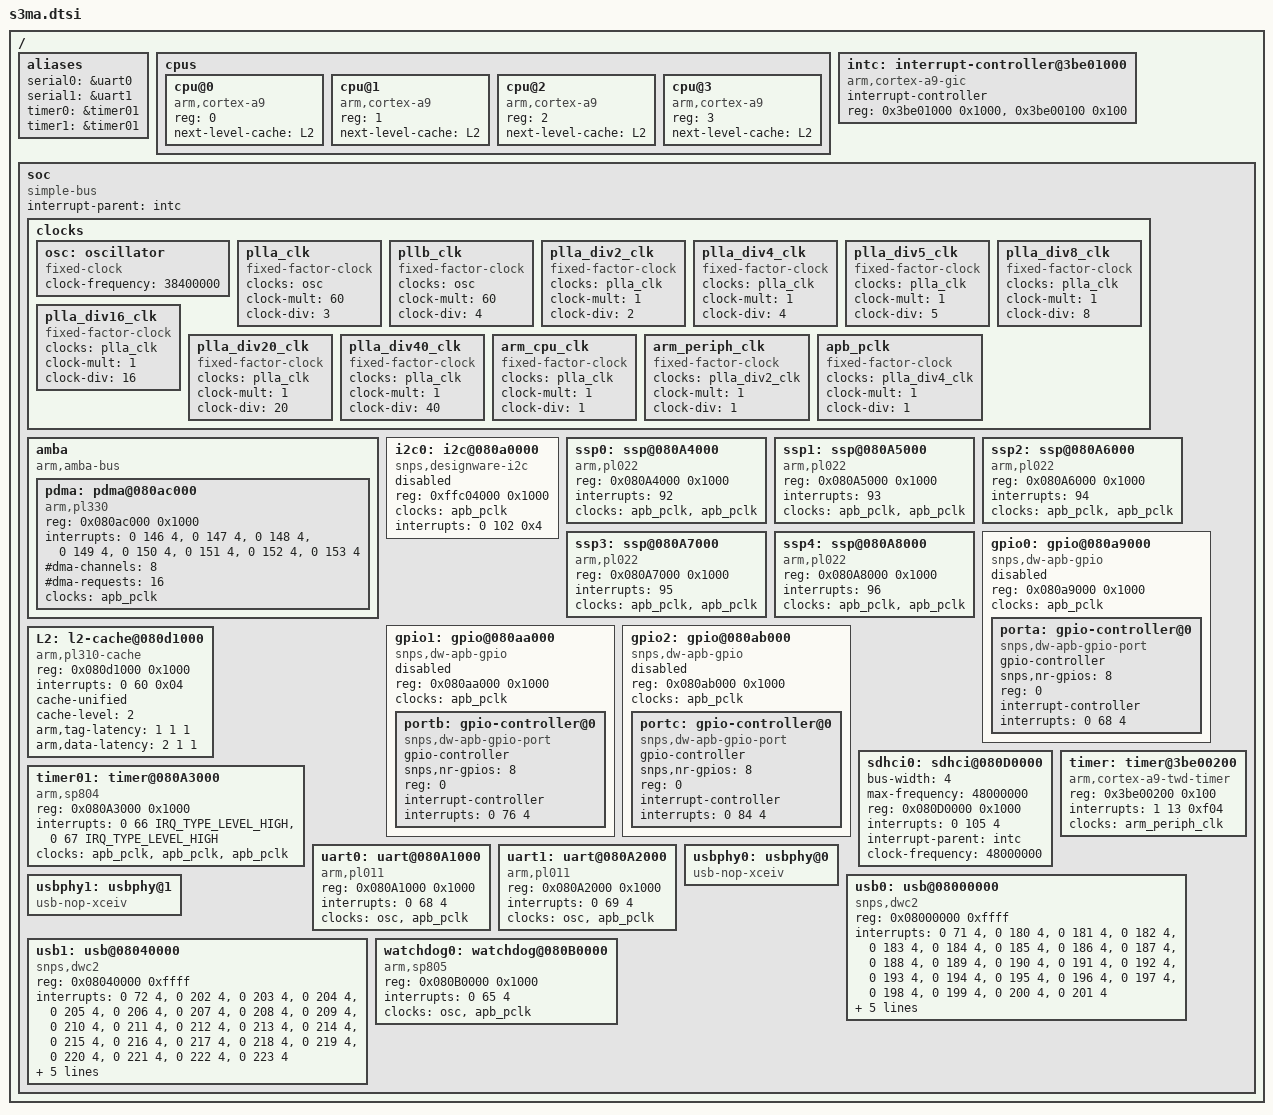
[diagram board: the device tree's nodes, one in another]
/*
 * Copyright 2015 Silver Bullet Technology
 *
 * This program is free software; you can redistribute it and/or modify
 * it under the terms of the GNU General Public License as published by
 * the Free Software Foundation; either version 2 of the License, or
 * (at your option) any later version.
 *
 * This program is distributed in the hope that it will be useful,
 * but WITHOUT ANY WARRANTY; without even the implied warranty of
 * MERCHANTABILITY or FITNESS FOR A PARTICULAR PURPOSE.  See the
 * GNU General Public License for more details.
 *
 * You should have received a copy of the GNU General Public License
 * along with this program.  If not, see <http://www.gnu.org/licenses/>.
 */

#include "skeleton.dtsi"
#include <dt-bindings/interrupt-controller/irq.h>
#include <dt-bindings/gpio/gpio.h>

/ {
	#address-cells = <1>;
	#size-cells = <1>;

	aliases {
		serial0 = &uart0;
		serial1 = &uart1;
		timer0 = &timer01;
		timer1 = &timer01;
	};

	cpus {
		#address-cells = <1>;
		#size-cells = <0>;

		cpu@0 {
			compatible = "arm,cortex-a9";
			device_type = "cpu";
			reg = <0>;
			next-level-cache = <&L2>;
		};
		cpu@1 {
			compatible = "arm,cortex-a9";
			device_type = "cpu";
			reg = <1>;
			next-level-cache = <&L2>;
		};
		cpu@2 {
			compatible = "arm,cortex-a9";
			device_type = "cpu";
			reg = <2>;
			next-level-cache = <&L2>;
		};
		cpu@3 {
			compatible = "arm,cortex-a9";
			device_type = "cpu";
			reg = <3>;
			next-level-cache = <&L2>;
		};
	};
	
	/* Add PMU */

	intc: interrupt-controller@3be01000 {
		compatible = "arm,cortex-a9-gic";
		#interrupt-cells = <3>;
		interrupt-controller;
		reg = <0x3be01000 0x1000>,
		      <0x3be00100 0x100>;
	};

	soc {
		#address-cells = <1>;
		#size-cells = <1>;
		compatible = "simple-bus";
		device_type = "soc";
		interrupt-parent = <&intc>;
		ranges;
		
		clocks {
			#address-cells = <1>;
			#size-cells = <0>;
	
			osc: oscillator {
				compatible = "fixed-clock";
				#clock-cells = <0>;
				clock-frequency = <38400000>;
                /* clock-output-names = "osc"; */
			};
			plla_clk: plla_clk {
				compatible = "fixed-factor-clock";
				#clock-cells = <0>;
				clocks = <&osc>;
				clock-mult = <60>;
				clock-div = <3>;
                /* clock-output-names = "plla_clk"; */
			};
			pllb_clk: pllb_clk {
				compatible = "fixed-factor-clock";
				#clock-cells = <0>;
				clocks = <&osc>;
				clock-mult = <60>;
				clock-div = <4>;
                /* clock-output-names = "pllb_clk"; */
			};
			plla_div2_clk: plla_div2_clk {
				compatible = "fixed-factor-clock";
				#clock-cells = <0>;
				clocks = <&plla_clk>;
				clock-mult = <1>;
				clock-div = <2>;
                /* clock-output-names = "plla_div2_clk"; */
			};
			plla_div4_clk: plla_div4_clk {
				compatible = "fixed-factor-clock";
				#clock-cells = <0>;
				clocks = <&plla_clk>;
				clock-mult = <1>;
				clock-div = <4>;
                /* clock-output-names = "plla_div4_clk"; */
			};
			plla_div5_clk: plla_div5_clk {
				compatible = "fixed-factor-clock";
				#clock-cells = <0>;
				clocks = <&plla_clk>;
				clock-mult = <1>;
				clock-div = <5>;
                /* clock-output-names = "plla_div5_clk"; */
			};
			plla_div8_clk: plla_div8_clk {
				compatible = "fixed-factor-clock";
				#clock-cells = <0>;
				clocks = <&plla_clk>;
				clock-mult = <1>;
				clock-div = <8>;
                /* clock-output-names = "plla_div8_clk"; */
			};
			plla_div16_clk: plla_div16_clk {
				compatible = "fixed-factor-clock";
				#clock-cells = <0>;
				clocks = <&plla_clk>;
				clock-mult = <1>;
				clock-div = <16>;
                /* clock-output-names = "plla_div16_clk"; */
			};			
			plla_div20_clk: plla_div20_clk {
				compatible = "fixed-factor-clock";
				#clock-cells = <0>;
				clocks = <&plla_clk>;
				clock-mult = <1>;
				clock-div = <20>;
                /* clock-output-names = "plla_div20_clk"; */
			};
			plla_div40_clk: plla_div40_clk {
				compatible = "fixed-factor-clock";
				#clock-cells = <0>;
				clocks = <&plla_clk>;
				clock-mult = <1>;
				clock-div = <40>;
                /* clock-output-names = "plla_div40_clk"; */
			};
			/* Generate the module clocks */
			arm_cpu_clk: arm_cpu_clk {
				compatible = "fixed-factor-clock";
				#clock-cells = <0>;
				clocks = <&plla_clk>;
				clock-mult = <1>;
				clock-div = <1>;
			};
			arm_periph_clk: arm_periph_clk {
				compatible = "fixed-factor-clock";
				#clock-cells = <0>;
				clocks = <&plla_div2_clk>;
				clock-mult = <1>;
				clock-div = <1>;
			};
			apb_pclk: apb_pclk {
				compatible = "fixed-factor-clock";
				#clock-cells = <0>;
				clocks = <&plla_div4_clk>;
				clock-mult = <1>;
				clock-div = <1>;
			};
		};
	
		amba {
			compatible = "arm,amba-bus";
			#address-cells = <1>;
			#size-cells = <1>;
			ranges;

			pdma: pdma@080ac000 {
				compatible = "arm,pl330", "arm,primecell";
				reg = <0x080ac000 0x1000>;
				interrupts = <0 146 4>,
					     <0 147 4>,
					     <0 148 4>,
					     <0 149 4>,
					     <0 150 4>,
					     <0 151 4>,
					     <0 152 4>,
					     <0 153 4>;
				#dma-cells = <1>;
				#dma-channels = <8>;
				#dma-requests = <16>;
				clocks = <&apb_pclk>;
				clock-names = "apb_pclk";
			};
		};

		i2c0: i2c@080a0000 {
			#address-cells = <1>;
			#size-cells = <0>;
			compatible = "snps,designware-i2c";
			reg = <0xffc04000 0x1000>;
			clocks = <&apb_pclk>;
			interrupts = <0 102 0x4>;
			status = "disabled";
		};

        ssp0: ssp@080A4000 {
            #address-cells = <1>;
            #size-cells = <0>;
            compatible = "arm,pl022", "arm,primecell";
            reg = <0x080A4000 0x1000>;
            interrupts = <92>;
            clocks = <&apb_pclk>, <&apb_pclk>;
            clock-names = "SSPCLK", "apb_pclk";
        };

        ssp1: ssp@080A5000 {
            #address-cells = <1>;
            #size-cells = <0>;
            compatible = "arm,pl022", "arm,primecell";
            reg = <0x080A5000 0x1000>;
            interrupts = <93>;
            clocks = <&apb_pclk>, <&apb_pclk>;
            clock-names = "SSPCLK", "apb_pclk";
        };

        ssp2: ssp@080A6000 {
            #address-cells = <1>;
            #size-cells = <0>;
            compatible = "arm,pl022", "arm,primecell";
            reg = <0x080A6000 0x1000>;
            interrupts = <94>;
            clocks = <&apb_pclk>, <&apb_pclk>;
            clock-names = "SSPCLK", "apb_pclk";
        };
                
        ssp3: ssp@080A7000 {
            #address-cells = <1>;
            #size-cells = <0>;
            compatible = "arm,pl022", "arm,primecell";
            reg = <0x080A7000 0x1000>;
            interrupts = <95>;
            clocks = <&apb_pclk>, <&apb_pclk>;
            clock-names = "SSPCLK", "apb_pclk";
        };
                
        ssp4: ssp@080A8000 {
            #address-cells = <1>;
            #size-cells = <0>;
            compatible = "arm,pl022", "arm,primecell";
            reg = <0x080A8000 0x1000>;
            interrupts = <96>;
            clocks = <&apb_pclk>, <&apb_pclk>;
            clock-names = "SSPCLK", "apb_pclk";
        };
                                
		gpio0: gpio@080a9000 {
			#address-cells = <1>;
			#size-cells = <0>;
			compatible = "snps,dw-apb-gpio";
			reg = <0x080a9000 0x1000>;
			clocks = <&apb_pclk>;
			status = "disabled";

			porta: gpio-controller@0 {
				compatible = "snps,dw-apb-gpio-port";
				gpio-controller;
				#gpio-cells = <2>;
				snps,nr-gpios = <8>;
				reg = <0>;
				interrupt-controller;
				#interrupt-cells = <2>;
				interrupts = <0 68 4>;
			};
		};

		gpio1: gpio@080aa000 {
			#address-cells = <1>;
			#size-cells = <0>;
			compatible = "snps,dw-apb-gpio";
			reg = <0x080aa000 0x1000>;
			clocks = <&apb_pclk>;
			status = "disabled";

			portb: gpio-controller@0 {
				compatible = "snps,dw-apb-gpio-port";
				gpio-controller;
				#gpio-cells = <2>;
				snps,nr-gpios = <8>;
				reg = <0>;
				interrupt-controller;
				#interrupt-cells = <2>;
				interrupts = <0 76 4>;
			};
		};

		gpio2: gpio@080ab000 {
			#address-cells = <1>;
			#size-cells = <0>;
			compatible = "snps,dw-apb-gpio";
			reg = <0x080ab000 0x1000>;
			clocks = <&apb_pclk>;
			status = "disabled";

			portc: gpio-controller@0 {
				compatible = "snps,dw-apb-gpio-port";
				gpio-controller;
				#gpio-cells = <2>;
				snps,nr-gpios = <8>;
				reg = <0>;
				interrupt-controller;
				#interrupt-cells = <2>;
				interrupts = <0 84 4>;
			};
		};

		L2: l2-cache@080d1000 {
			compatible = "arm,pl310-cache";
			reg = <0x080d1000 0x1000>;
			interrupts = <0 60 0x04>;
			cache-unified;
			cache-level = <2>;
			arm,tag-latency = <1 1 1>;
			arm,data-latency = <2 1 1>;
		};

        sdhci0: sdhci@080D0000 {
            status = "okay";
            bus-width = <4>;   
            max-frequency = <48000000>;    
            reg = <0x080D0000 0x1000>;
            interrupts = <0 105  4>;
            interrupt-parent = <&intc>;
            /* clocks = <&clkc 21>, <&clkc 32>; */
            clock-frequency = <48000000>;
        };

		/* Local timer */
		timer: timer@3be00200 {
			compatible = "arm,cortex-a9-twd-timer";
			reg = <0x3be00200 0x100>;
			interrupts = <1 13 0xf04>;
			clocks = <&arm_periph_clk>;
		};

		/* Primecell timers */
		timer01: timer@080A3000 {
			compatible = "arm,sp804", "arm,primecell";
			reg = <0x080A3000 0x1000>;
			interrupts = <0 66 IRQ_TYPE_LEVEL_HIGH>, <0 67 IRQ_TYPE_LEVEL_HIGH>; 
			clocks = <&apb_pclk>, <&apb_pclk>, <&apb_pclk>;
			clock-names = "timer1", "timer2", "apb_pclk";
        };
        uart0: uart@080A1000 {
            compatible = "arm,pl011", "arm,primecell";
            reg = <0x080A1000 0x1000>;
            interrupts = <0 68 4>;
            clocks = <&osc>, <&apb_pclk>;
            clock-names = "uartclk", "apb_pclk";
        };

        uart1: uart@080A2000 {
            compatible = "arm,pl011", "arm,primecell";
            reg = <0x080A2000 0x1000>;
            interrupts = <0 69 4>;
            clocks = <&osc>, <&apb_pclk>;
            clock-names = "uartclk", "apb_pclk";
        };

		usbphy0: usbphy@0 {
			#phy-cells = <0>;
			compatible = "usb-nop-xceiv";
			status = "okay";
		};

		usb0: usb@08000000 {
			compatible = "snps,dwc2";
			reg = <0x08000000 0xffff>;
			interrupts = <0 71 4>,
			             <0 180 4>, <0 181 4>, <0 182 4>, <0 183 4>,
			             <0 184 4>, <0 185 4>, <0 186 4>, <0 187 4>,
			             <0 188 4>, <0 189 4>, <0 190 4>, <0 191 4>,
			             <0 192 4>, <0 193 4>, <0 194 4>, <0 195 4>,
			             <0 196 4>, <0 197 4>, <0 198 4>, <0 199 4>,
			             <0 200 4>, <0 201 4>;
			clocks = <&apb_pclk>;
			clock-names = "otg";
			phys = <&usbphy0>;
			phy-names = "usb2-phy";
			dr-mode = "peripheral";

			g-rx-fifo-size = <128>;
			g-tx-fifo-size = <128>,<128>,<128>,<128>;
		};

		usbphy1: usbphy@1 {
			#phy-cells = <0>;
			compatible = "usb-nop-xceiv";
			status = "okay";
		};

		usb1: usb@08040000 {
			compatible = "snps,dwc2";
			reg = <0x08040000 0xffff>;
			interrupts = <0 72 4>,
			             <0 202 4>, <0 203 4>, <0 204 4>, <0 205 4>,
			             <0 206 4>, <0 207 4>, <0 208 4>, <0 209 4>,
			             <0 210 4>, <0 211 4>, <0 212 4>, <0 213 4>,
			             <0 214 4>, <0 215 4>, <0 216 4>, <0 217 4>,
			             <0 218 4>, <0 219 4>, <0 220 4>, <0 221 4>,
			             <0 222 4>, <0 223 4>;
			clocks = <&apb_pclk>;
			clock-names = "otg";
			phys = <&usbphy1>;
			phy-names = "usb2-phy";
			dr-mode = "peripheral";

			g-rx-fifo-size = <128>;
			g-tx-fifo-size = <128>,<128>,<128>,<128>;
		};

		watchdog0: watchdog@080B0000 {
            compatible = "arm,sp805", "arm,primecell";
			reg = <0x080B0000 0x1000>;
			interrupts = <0 65 4>;
			clocks = <&osc>, <&apb_pclk>;
			clock-names = "wdogclk", "apb_pclk";
		};

	};
};
